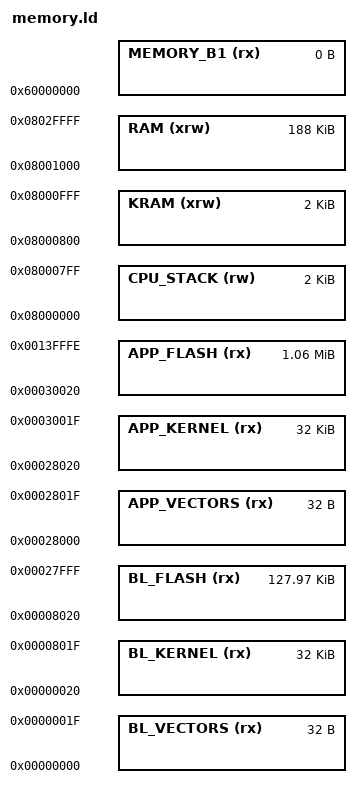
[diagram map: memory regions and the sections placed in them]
MEMORY
{
  BL_VECTORS(rx)      : ORIGIN = 0x00000000, LENGTH = 0x00000020
  BL_KERNEL (rx)      : ORIGIN = 0x00000020, LENGTH = 0x00008000
  BL_FLASH  (rx)      : ORIGIN = 0x00008020, LENGTH = (0x00028000 - 0x00008020)
  APP_VECTORS(rx)     : ORIGIN = 0x00028000, LENGTH = 0x00000020
  APP_KERNEL (rx)     : ORIGIN = 0x00028020, LENGTH = 0x00008000
  APP_FLASH  (rx)     : ORIGIN = 0x00030020, LENGTH = (0x0013ffff - 0x00030020)
  CPU_STACK (rw)      : ORIGIN = 0x08000000, LENGTH = 0x00000800 /* Stack is configured in sys_core.asm */
  KRAM (xrw)          : ORIGIN = 0x08000800, LENGTH = 0x00000800
  RAM (xrw)           : ORIGIN = (0x08000800 + 0x00000800), LENGTH = (0x0002f800 - 0x00000800)
  MEMORY_B1 (rx)      : ORIGIN = 0x60000000, LENGTH = 0K
}
